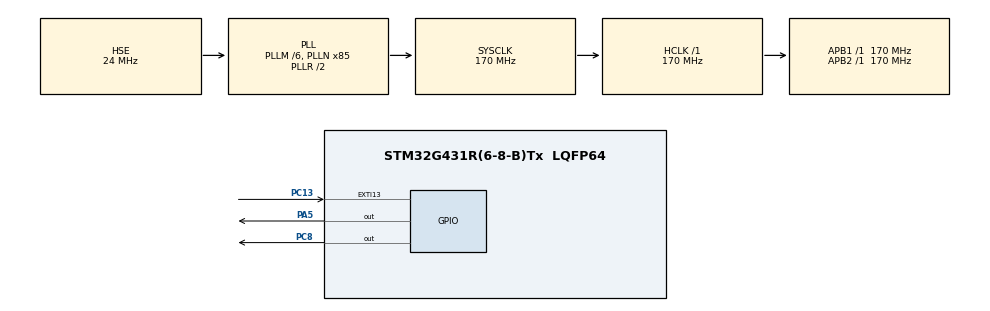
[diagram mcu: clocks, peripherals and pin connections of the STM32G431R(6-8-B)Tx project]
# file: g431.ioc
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Dma.MEMTOMEM.0.Direction=DMA_MEMORY_TO_MEMORY
Dma.MEMTOMEM.0.EventEnable=DISABLE
Dma.MEMTOMEM.0.Instance=DMA1_Channel1
Dma.MEMTOMEM.0.MemDataAlignment=DMA_MDATAALIGN_WORD
Dma.MEMTOMEM.0.MemInc=DMA_MINC_DISABLE
Dma.MEMTOMEM.0.Mode=DMA_NORMAL
Dma.MEMTOMEM.0.PeriphDataAlignment=DMA_PDATAALIGN_WORD
Dma.MEMTOMEM.0.PeriphInc=DMA_PINC_ENABLE
Dma.MEMTOMEM.0.Polarity=HAL_DMAMUX_REQ_GEN_RISING
Dma.MEMTOMEM.0.Priority=DMA_PRIORITY_LOW
Dma.MEMTOMEM.0.RequestNumber=1
Dma.MEMTOMEM.0.SignalID=NONE
Dma.MEMTOMEM.0.SyncEnable=DISABLE
Dma.MEMTOMEM.0.SyncPolarity=HAL_DMAMUX_SYNC_NO_EVENT
Dma.MEMTOMEM.0.SyncRequestNumber=1
Dma.MEMTOMEM.0.SyncSignalID=NONE
Dma.Request0=MEMTOMEM
Mcu.Family=STM32G4
Mcu.Name=STM32G431R(6-8-B)Tx
Mcu.Package=LQFP64
NUCLEO-G431RB.BUTTON=1
NUCLEO-G431RB.LD1=true
NUCLEO-G431RB.VCP=true
NVIC.DMA1_Channel1_IRQn=true\:0\:0\:false\:false\:true\:true\:true\:true
NVIC.EXTI15_10_IRQn=true\:0\:0\:false\:false\:true\:false\:true\:true
NVIC.PriorityGroup=NVIC_PRIORITYGROUP_4
NVIC.TIM1_UP_TIM16_IRQn=true\:0\:0\:false\:false\:true\:true\:true\:true
PA13.GPIO_Label=T_SWDIO
PA13.Mode=Serial_Wire
PA13.Signal=SYS_JTMS-SWDIO
PA14.GPIO_Label=T_SWCLK
PA14.Mode=Serial_Wire
PA14.Signal=SYS_JTCK-SWCLK
PA2.Signal=LPUART1_TX
PA3.Signal=LPUART1_RX
PA5.Signal=GPIO_Output
PB3.GPIO_Label=T_SWO
PB3.Signal=SYS_JTDO-SWO
PC13.Signal=GPXTI13
PC14-OSC32_IN.GPIO_Label=RCC_OSC32_OUT
PC14-OSC32_IN.Signal=RCC_OSC32_IN
PC15-OSC32_OUT.GPIO_Label=RCC_OSC32_OUT
PC15-OSC32_OUT.Signal=RCC_OSC32_OUT
PC8.GPIO_ModeDefaultOutputPP=GPIO_MODE_OUTPUT_OD
PC8.GPIO_PuPd=GPIO_NOPULL
PC8.GPIO_Speed=GPIO_SPEED_FREQ_VERY_HIGH
PC8.PinState=GPIO_PIN_SET
PC8.Signal=GPIO_Output
PF0-OSC_IN.GPIO_Label=RCC_OSC_IN
PF0-OSC_IN.Mode=HSE-External-Oscillator
PF0-OSC_IN.Signal=RCC_OSC_IN
PF1-OSC_OUT.GPIO_Label=RCC_OSC_OUT
PF1-OSC_OUT.Mode=HSE-External-Oscillator
PF1-OSC_OUT.Signal=RCC_OSC_OUT
ProjectManager.HeapSize=0x200
ProjectManager.StackSize=0x400
ProjectManager.TargetToolchain=STM32CubeIDE
RCC.ADC12Freq_Value=170000000
RCC.AHBFreq_Value=170000000
RCC.APB1Freq_Value=170000000
RCC.APB1TimFreq_Value=170000000
RCC.APB2Freq_Value=170000000
RCC.APB2TimFreq_Value=170000000
RCC.CortexFreq_Value=170000000
RCC.EXTERNAL_CLOCK_VALUE=12288000
RCC.HCLKFreq_Value=170000000
RCC.HSE_VALUE=24000000
RCC.HSI48_VALUE=48000000
RCC.HSI_VALUE=16000000
RCC.LSE_VALUE=32768
RCC.PLLM=RCC_PLLM_DIV6
RCC.PLLN=85
RCC.PLLSourceVirtual=RCC_PLLSOURCE_HSE
RCC.RTCClockSelection=RCC_RTCCLKSOURCE_LSE
RCC.SYSCLKFreq_VALUE=170000000
RCC.SYSCLKSource=RCC_SYSCLKSOURCE_PLLCLK
RCC.USBFreq_Value=170000000
RCC.VCOOutputFreq_Value=340000000
TIM1.AutoReloadPreload=TIM_AUTORELOAD_PRELOAD_DISABLE
TIM1.PeriodNoDither=65535
TIM1.Prescaler=170-1
TIM1.TIM_MasterOutputTrigger=TIM_TRGO_ENABLE
VP_NUCLEO-G431RB_VS_BSP_COMMON.Mode=COMMON
VP_SYS_VS_DBSignals.Mode=DisableDeadBatterySignals
VP_TIM1_VS_ClockSourceINT.Mode=Internal
board=NUCLEO-G431RB

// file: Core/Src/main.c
/* USER CODE BEGIN Header */
/**
  ******************************************************************************
  * @file           : main.c
  * @brief          : Main program body
  ******************************************************************************
  * @attention
  *
  * Copyright (c) 2025 STMicroelectronics.
  * All rights reserved.
  *
  * This software is licensed under terms that can be found in the LICENSE file
  * in the root directory of this software component.
  * If no LICENSE file comes with this software, it is provided AS-IS.
  *
  ******************************************************************************
  */
/* USER CODE END Header */
#include "main.h"
#include "dma.h"
#include "tim.h"
#include "gpio.h"

/* USER CODE BEGIN Includes */
#include <ow.h>
ow_handle_t ds18;

void ds18_tim_cb(TIM_HandleTypeDef *htim)
{
  ow_callback(&ds18);
}

/* USER CODE END Includes */

COM_InitTypeDef BspCOMInit;

void SystemClock_Config(void);

int main(void)
{

  /* MCU Configuration--------------------------------------------------------*/

  /* Reset of all peripherals, Initializes the Flash interface and the Systick. */
  HAL_Init();

  /* Configure the system clock */
  SystemClock_Config();

  /* Initialize all configured peripherals */
  MX_GPIO_Init();
  MX_DMA_Init();
  MX_TIM1_Init();

  /* Initialize leds */
  BSP_LED_Init(LED_GREEN);

  /* Initialize USER push-button, will be used to trigger an interrupt each time it's pressed.*/
  BSP_PB_Init(BUTTON_USER, BUTTON_MODE_EXTI);

  /* Initialize COM1 port (115200, 8 bits (7-bit data + 1 stop bit), no parity */
  BspCOMInit.BaudRate   = 115200;
  BspCOMInit.WordLength = COM_WORDLENGTH_8B;
  BspCOMInit.StopBits   = COM_STOPBITS_1;
  BspCOMInit.Parity     = COM_PARITY_NONE;
  BspCOMInit.HwFlowCtl  = COM_HWCONTROL_NONE;
  if (BSP_COM_Init(COM1, &BspCOMInit) != BSP_ERROR_NONE)
  {
    Error_Handler();
  }

  /* Infinite loop */
  /* USER CODE BEGIN WHILE */
  ow_init_t ow_init_struct;
  ow_init_struct.tim_handle = &htim1;
  ow_init_struct.gpio = GPIOC;
  ow_init_struct.pin = GPIO_PIN_8;
  ow_init_struct.tim_cb = ds18_tim_cb;
  ow_init(&ds18 , &ow_init_struct);

  HAL_Delay(100);

//  ow_write(&ds18, 0x44, NULL, 0);
//  HAL_Delay(1000);
//  ow_read(&ds18, 0xBE, 9);

//  ow_read_id(&ds18);

  ow_update_all_id(&ds18);

  while (1)
  {
    HAL_Delay(10);

    /* USER CODE END WHILE */

  }
}

void SystemClock_Config(void)
{
  RCC_OscInitTypeDef RCC_OscInitStruct = {0};
  RCC_ClkInitTypeDef RCC_ClkInitStruct = {0};

  /** Configure the main internal regulator output voltage
  */
  HAL_PWREx_ControlVoltageScaling(PWR_REGULATOR_VOLTAGE_SCALE1_BOOST);

  /** Initializes the RCC Oscillators according to the specified parameters
  * in the RCC_OscInitTypeDef structure.
  */
  RCC_OscInitStruct.OscillatorType = RCC_OSCILLATORTYPE_HSE;
  RCC_OscInitStruct.HSEState = RCC_HSE_ON;
  RCC_OscInitStruct.PLL.PLLState = RCC_PLL_ON;
  RCC_OscInitStruct.PLL.PLLSource = RCC_PLLSOURCE_HSE;
  RCC_OscInitStruct.PLL.PLLM = RCC_PLLM_DIV6;
  RCC_OscInitStruct.PLL.PLLN = 85;
  RCC_OscInitStruct.PLL.PLLP = RCC_PLLP_DIV2;
  RCC_OscInitStruct.PLL.PLLQ = RCC_PLLQ_DIV2;
  RCC_OscInitStruct.PLL.PLLR = RCC_PLLR_DIV2;
  if (HAL_RCC_OscConfig(&RCC_OscInitStruct) != HAL_OK)
  {
    Error_Handler();
  }

  /** Initializes the CPU, AHB and APB buses clocks
  */
  RCC_ClkInitStruct.ClockType = RCC_CLOCKTYPE_HCLK|RCC_CLOCKTYPE_SYSCLK
                              |RCC_CLOCKTYPE_PCLK1|RCC_CLOCKTYPE_PCLK2;
  RCC_ClkInitStruct.SYSCLKSource = RCC_SYSCLKSOURCE_PLLCLK;
  RCC_ClkInitStruct.AHBCLKDivider = RCC_SYSCLK_DIV1;
  RCC_ClkInitStruct.APB1CLKDivider = RCC_HCLK_DIV1;
  RCC_ClkInitStruct.APB2CLKDivider = RCC_HCLK_DIV1;

  if (HAL_RCC_ClockConfig(&RCC_ClkInitStruct, FLASH_LATENCY_4) != HAL_OK)
  {
    Error_Handler();
  }
}

void Error_Handler(void)
{
  __disable_irq();
  while (1)
  {
  }
}
